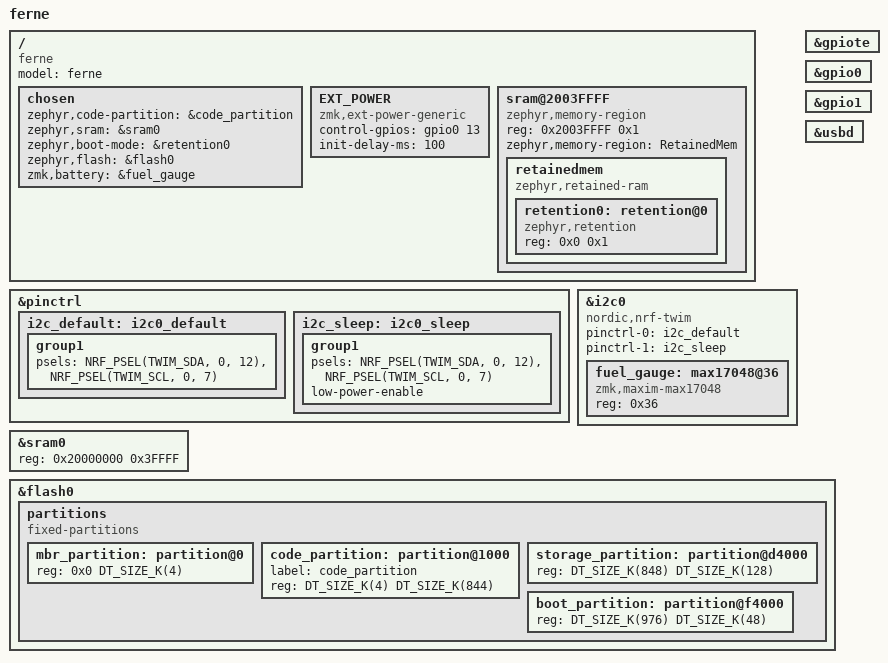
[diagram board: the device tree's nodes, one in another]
/*
 * Copyright (c) 2025 The ZMK Contributors
 *
 * SPDX-License-Identifier: MIT
 */

/dts-v1/;
#include <nordic/nrf52840_qiaa.dtsi>
#include <dt-bindings/zmk/matrix_transform.h>
#include <dt-bindings/led/led.h>
#include <dt-bindings/zmk/ext_power.h>
#include <physical_layouts.dtsi>
#include <zephyr/dt-bindings/input/input-event-codes.h>

/ {
	model = "ferne";
	compatible = "ferne";

	chosen {
		zephyr,code-partition = &code_partition;
		zephyr,sram = &sram0;
		zephyr,boot-mode = &retention0;
		zephyr,flash = &flash0;
		zmk,battery = &fuel_gauge;
	};

	EXT_POWER {
        compatible = "zmk,ext-power-generic";
        control-gpios = <&gpio0 13 (GPIO_ACTIVE_HIGH | GPIO_PULL_DOWN)>;
        init-delay-ms = <100>;
    };

	// nrf52840 has 256kb of RAM. Dedicate last byte for retained-ram
	sram@2003FFFF {
		compatible = "zephyr,memory-region", "mmio-sram";
		reg = <0x2003FFFF 0x1>;
		zephyr,memory-region = "RetainedMem";
		status = "okay";

		retainedmem {
				compatible = "zephyr,retained-ram";
				status = "okay";
				#address-cells = <1>;
				#size-cells = <1>;

				retention0: retention@0 {
						compatible = "zephyr,retention";
						status = "okay";
						reg = <0x0 0x1>;
				};
		};
	};
};

&pinctrl {
	i2c_default: i2c0_default {
		group1 {
			psels = <NRF_PSEL(TWIM_SDA, 0, 12)>,
					<NRF_PSEL(TWIM_SCL, 0, 7)>;
		};
	};

	i2c_sleep: i2c0_sleep {
		group1 {
			psels = <NRF_PSEL(TWIM_SDA, 0, 12)>,
					<NRF_PSEL(TWIM_SCL, 0, 7)>;
			low-power-enable;
		};
	};
};

&i2c0 {
	status = "okay";
	compatible = "nordic,nrf-twim";
	pinctrl-0 = <&i2c_default>;
	pinctrl-1 = <&i2c_sleep>;
	pinctrl-names = "default", "sleep";
	// clock-frequency = <100000>;

	fuel_gauge: max17048@36 {
		compatible = "zmk,maxim-max17048";
		status = "okay";
		//label = "BATTERY"; //deprecated
		reg = <0x36>;
	};

	// charger: bq25895@6a {
	// 	compatible = "ti,bq25895";
	// 	status = "okay";
	// 	// label = "BATTERY";
	// 	reg = <0x6a>;
	// 	// FIX PIN
	// 	irq-gpios = <&gpio0 17 (GPIO_ACTIVE_LOW | GPIO_PULL_UP)>;
	// 	//status = <&led_animation 5>;
	// 	//status-bar = <5 6 10 8>;
	// };
};

&gpiote {
	status = "okay";
};

&gpio0 {
	status = "okay";
};

&gpio1 {
	status = "okay";
};

zephyr_udc0: &usbd {
	status = "okay";
};

/* Reduce SRAM0 usage by 1 byte to account for retained area */
&sram0 {
	reg = <0x20000000 0x3FFFF>;
};

&flash0 {
	partitions {
		compatible = "fixed-partitions";
		#address-cells = <1>;
		#size-cells = <1>;

		// Don't move: Adafruit MBR partition
		// Without SoftDevice, Adafruit bootloader writes to the start of flash
		// References: Adafruit_nRF52_Bootloader/lib/sdk11/components/libraries/bootloader_dfu/bootloader.c:bootloader_app_start
		//             https://github.com/adafruit/Adafruit_nRF52_Bootloader/pull/128
		mbr_partition: partition@0 {
			reg = <0x0 DT_SIZE_K(4)>;
		};

		code_partition: partition@1000 {
			label = "code_partition";
			reg = <DT_SIZE_K(4) DT_SIZE_K(844)>;
		};

		// /*
		//  * Storage partition will be used by FCB/LittleFS/NVS
		//  * if enabled.
		//  * See https://docs.nordicsemi.com/bundle/ncs-latest/page/zephyr/services/storage/nvs/nvs.html#flash_wear
		//  */
		storage_partition: partition@d4000 {
			reg = <DT_SIZE_K(848) DT_SIZE_K(128)>;
		};

		// Address 0xf4000 is hardcoded at https://github.com/adafruit/Adafruit_nRF52_Bootloader/blob/master/linker/nrf52840.ld
		// last build took 31612 bytes
		// TODO: MCUBoot?
		boot_partition: partition@f4000 {
			// label = "adafruit_boot"; // 48kb
			reg = <DT_SIZE_K(976) DT_SIZE_K(48)>;
		};
	};
};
